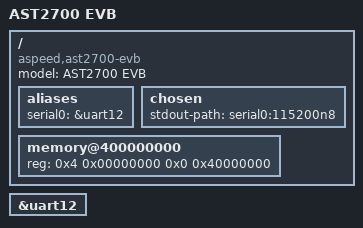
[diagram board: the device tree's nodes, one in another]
// SPDX-License-Identifier: GPL-2.0-only OR MIT
/*
 * Device Tree Source AST2700 EVB
 *
 * Copyright (C) ASPEED Technology Inc.
 */

/dts-v1/;
#include "aspeed-g7-a35.dtsi"

/ {
	model = "AST2700 EVB";
	compatible = "aspeed,ast2700-evb", "aspeed,ast2700";

	aliases {
	    serial0 = &uart12;  /* console port */
	};

	chosen {
		stdout-path = "serial0:115200n8";
	};

	memory@400000000 {
		device_type = "memory";
		reg = <0x4 0x00000000 0x0 0x40000000>;
	};
};

&uart12 {
	status = "okay";
};
